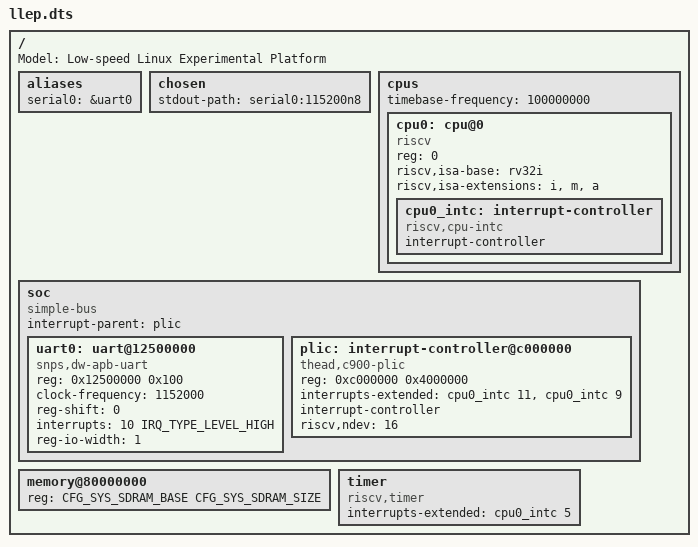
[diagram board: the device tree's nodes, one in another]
// SPDX-License-Identifier: GPL-2.0+
/*
 * Copyright (C) 2021, Bin Meng <bmeng.cn@gmail.com>
 */

/dts-v1/;
#include <dt-bindings/interrupt-controller/irq.h>
#include "configs/llep.h"

/ {

    Model = "Low-speed Linux Experimental Platform";

    #address-cells = <1>;
    #size-cells = <1>;

	aliases {
		serial0 = &uart0;
	};

	chosen {
		stdout-path = "serial0:115200n8";
	};

    cpus {
		#address-cells = <1>;
		#size-cells = <0>;
		timebase-frequency = <100000000>;

		cpu0: cpu@0 {
			compatible = "riscv";
			reg = <0>;
			device_type = "cpu";
			riscv,isa-base = "rv32i";
			riscv,isa-extensions = "i", "m", "a";

			cpu0_intc: interrupt-controller {
				compatible = "riscv,cpu-intc";
				interrupt-controller;
				#interrupt-cells = <1>;
			};
		};
    };

	soc {
		#address-cells = <1>;
		#size-cells = <1>;
		interrupt-parent = <&plic>;
		compatible = "simple-bus";
		ranges;

		uart0: uart@12500000 {
			compatible = "snps,dw-apb-uart", "ns16550a", "ns16550", "ns8250";
			reg = <0x12500000 0x100>;
			clock-frequency = <1152000>;
			reg-shift = <0>;
			interrupts = <10 IRQ_TYPE_LEVEL_HIGH>;
			reg-io-width = <1>;
			status = "okay";
			bootph-all;
		};

		plic: interrupt-controller@c000000 {
			compatible = "thead,c900-plic";
			reg = <0xc000000 0x4000000>;
			interrupts-extended = <&cpu0_intc 11>, <&cpu0_intc 9>;
			interrupt-controller;
			#interrupt-cells = <2>;
			#address-cells = <0>;
			riscv,ndev = <16>;
		};
	};

	memory@80000000 {
	    device_type = "memory";
    	reg = <CFG_SYS_SDRAM_BASE CFG_SYS_SDRAM_SIZE>;
    };

    timer {
		compatible = "riscv,timer";
		interrupts-extended = <&cpu0_intc 5>;
    };
};
